# MOTOR register map
Registers are 32-bit, access not given, no defined reset value unless marked. A register's access mark holds for its fields unless they carry their own. Addresses are absolute; registers are grouped by the start of their names; [hi:lo] are bit positions; {n}, {i} and the like mark numbered series.

## OPTIONREG0
{0x40069200+4i} OPTIONREG0_{i}_0 (i=0..7)
  [15:0] TIMEBASE_OR0_{i}
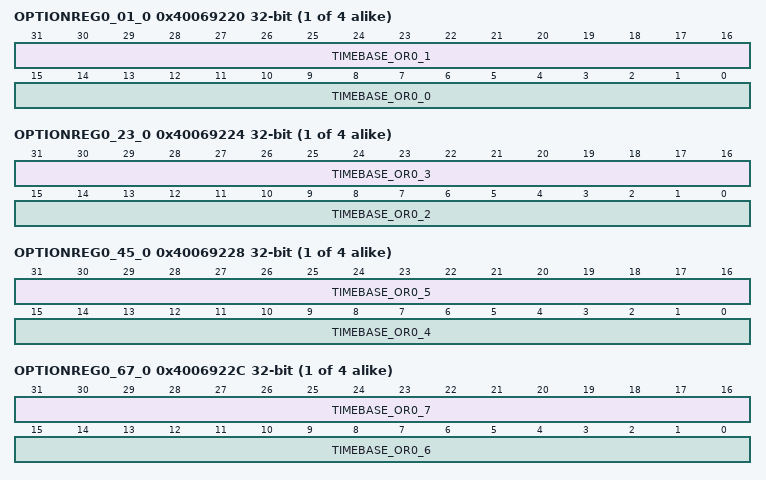
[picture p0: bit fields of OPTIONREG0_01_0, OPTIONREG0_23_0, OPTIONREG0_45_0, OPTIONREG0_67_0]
{0x40069220+0x400*i} OPTIONREG0_01_{i} (i=0..3)
  [31:16] TIMEBASE_OR0_1, [15:0] TIMEBASE_OR0_0
{0x40069224+0x400*i} OPTIONREG0_23_{i} (i=0..3)
  [31:16] TIMEBASE_OR0_3, [15:0] TIMEBASE_OR0_2
{0x40069228+0x400*i} OPTIONREG0_45_{i} (i=0..3)
  [31:16] TIMEBASE_OR0_5, [15:0] TIMEBASE_OR0_4
{0x4006922C+0x400*i} OPTIONREG0_67_{i} (i=0..3)
  [31:16] TIMEBASE_OR0_7, [15:0] TIMEBASE_OR0_6
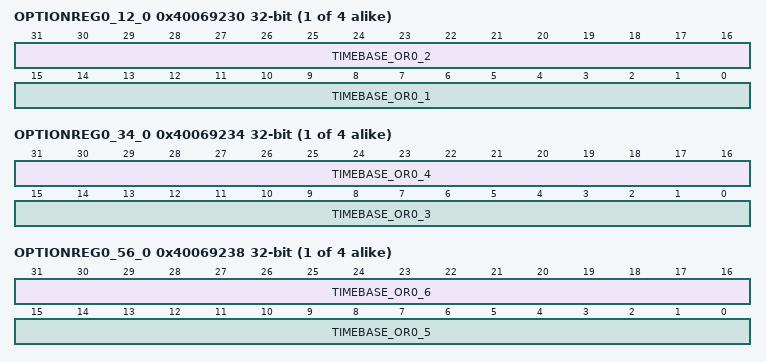
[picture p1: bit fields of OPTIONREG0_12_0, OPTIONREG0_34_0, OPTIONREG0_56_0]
{0x40069230+0x400*i} OPTIONREG0_12_{i} (i=0..3)
  [31:16] TIMEBASE_OR0_2, [15:0] TIMEBASE_OR0_1
{0x40069234+0x400*i} OPTIONREG0_34_{i} (i=0..3)
  [31:16] TIMEBASE_OR0_4, [15:0] TIMEBASE_OR0_3
{0x40069238+0x400*i} OPTIONREG0_56_{i} (i=0..3)
  [31:16] TIMEBASE_OR0_6, [15:0] TIMEBASE_OR0_5
{0x40069600+4i} OPTIONREG0_{i}_1 (i=0..7)
  [15:0] TIMEBASE_OR0_{i}
{0x40069A00+4i} OPTIONREG0_{i}_2 (i=0..7)
  [15:0] TIMEBASE_OR0_{i}
{0x40069E00+4i} OPTIONREG0_{i}_3 (i=0..7)
  [15:0] TIMEBASE_OR0_{i}

## OPTIONREG1
{0x40069240+4i} OPTIONREG1_{i}_0 (i=0..7)
  [15:0] TIMEBASE_OR1_{i}
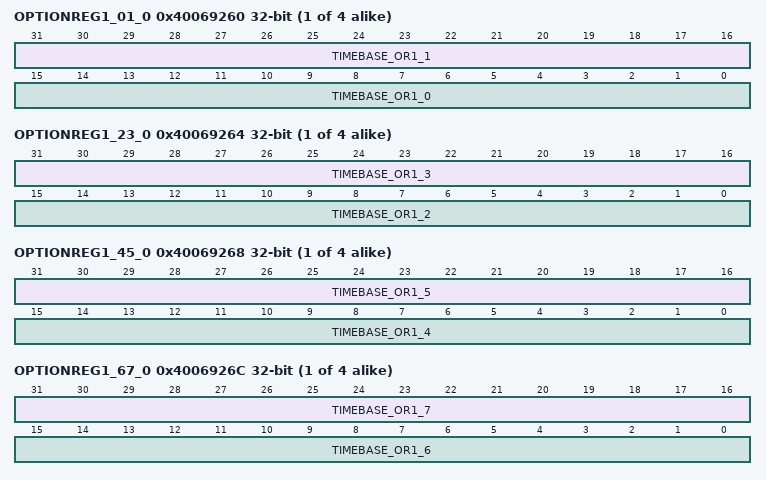
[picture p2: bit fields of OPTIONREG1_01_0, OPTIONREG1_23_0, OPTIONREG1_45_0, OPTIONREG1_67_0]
{0x40069260+0x400*i} OPTIONREG1_01_{i} (i=0..3)
  [31:16] TIMEBASE_OR1_1, [15:0] TIMEBASE_OR1_0
{0x40069264+0x400*i} OPTIONREG1_23_{i} (i=0..3)
  [31:16] TIMEBASE_OR1_3, [15:0] TIMEBASE_OR1_2
{0x40069268+0x400*i} OPTIONREG1_45_{i} (i=0..3)
  [31:16] TIMEBASE_OR1_5, [15:0] TIMEBASE_OR1_4
{0x4006926C+0x400*i} OPTIONREG1_67_{i} (i=0..3)
  [31:16] TIMEBASE_OR1_7, [15:0] TIMEBASE_OR1_6
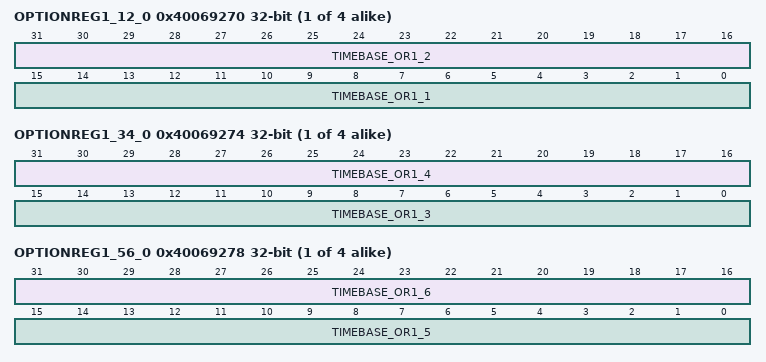
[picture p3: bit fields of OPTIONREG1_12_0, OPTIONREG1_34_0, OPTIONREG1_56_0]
{0x40069270+0x400*i} OPTIONREG1_12_{i} (i=0..3)
  [31:16] TIMEBASE_OR1_2, [15:0] TIMEBASE_OR1_1
{0x40069274+0x400*i} OPTIONREG1_34_{i} (i=0..3)
  [31:16] TIMEBASE_OR1_4, [15:0] TIMEBASE_OR1_3
{0x40069278+0x400*i} OPTIONREG1_56_{i} (i=0..3)
  [31:16] TIMEBASE_OR1_6, [15:0] TIMEBASE_OR1_5
{0x40069640+4i} OPTIONREG1_{i}_1 (i=0..7)
  [15:0] TIMEBASE_OR1_{i}
{0x40069A40+4i} OPTIONREG1_{i}_2 (i=0..7)
  [15:0] TIMEBASE_OR1_{i}
{0x40069E40+4i} OPTIONREG1_{i}_3 (i=0..7)
  [15:0] TIMEBASE_OR1_{i}

## OPTIONREG2
{0x40069280+4i} OPTIONREG2_{i}_0 (i=0..7)
  [15:0] TIMEBASE_OR2_{i}
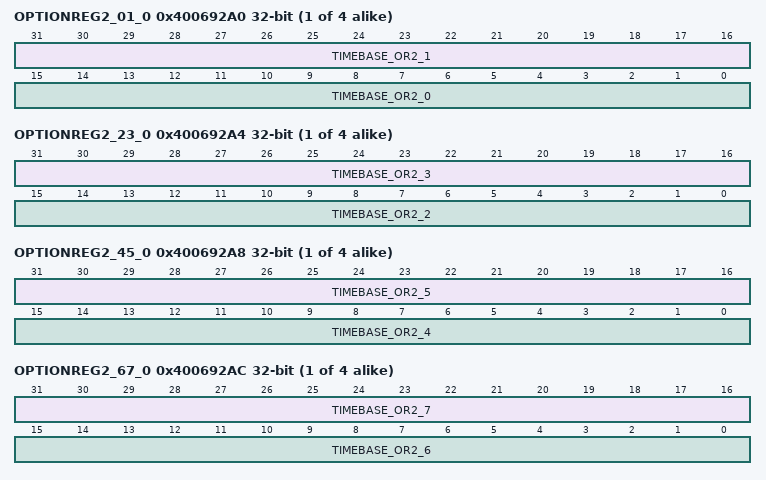
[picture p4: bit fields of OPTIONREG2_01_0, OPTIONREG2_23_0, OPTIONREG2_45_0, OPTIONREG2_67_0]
{0x400692A0+0x400*i} OPTIONREG2_01_{i} (i=0..3)
  [31:16] TIMEBASE_OR2_1, [15:0] TIMEBASE_OR2_0
{0x400692A4+0x400*i} OPTIONREG2_23_{i} (i=0..3)
  [31:16] TIMEBASE_OR2_3, [15:0] TIMEBASE_OR2_2
{0x400692A8+0x400*i} OPTIONREG2_45_{i} (i=0..3)
  [31:16] TIMEBASE_OR2_5, [15:0] TIMEBASE_OR2_4
{0x400692AC+0x400*i} OPTIONREG2_67_{i} (i=0..3)
  [31:16] TIMEBASE_OR2_7, [15:0] TIMEBASE_OR2_6
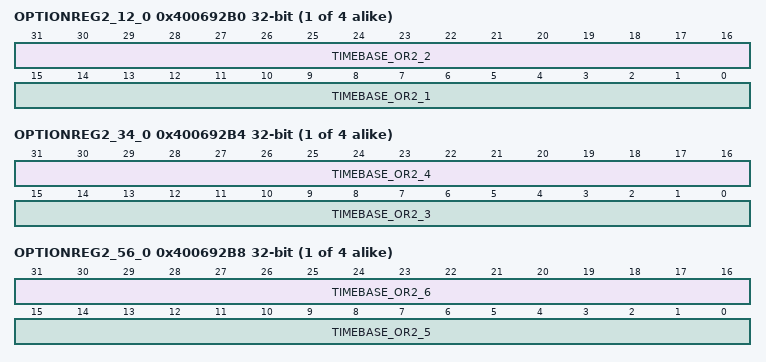
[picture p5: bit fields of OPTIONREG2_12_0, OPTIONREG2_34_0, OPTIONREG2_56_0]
{0x400692B0+0x400*i} OPTIONREG2_12_{i} (i=0..3)
  [31:16] TIMEBASE_OR2_2, [15:0] TIMEBASE_OR2_1
{0x400692B4+0x400*i} OPTIONREG2_34_{i} (i=0..3)
  [31:16] TIMEBASE_OR2_4, [15:0] TIMEBASE_OR2_3
{0x400692B8+0x400*i} OPTIONREG2_56_{i} (i=0..3)
  [31:16] TIMEBASE_OR2_6, [15:0] TIMEBASE_OR2_5
{0x40069680+4i} OPTIONREG2_{i}_1 (i=0..7)
  [15:0] TIMEBASE_OR2_{i}
{0x40069A80+4i} OPTIONREG2_{i}_2 (i=0..7)
  [15:0] TIMEBASE_OR2_{i}
{0x40069E80+4i} OPTIONREG2_{i}_3 (i=0..7)
  [15:0] TIMEBASE_OR2_{i}

## OPTIONREG3
{0x400692C0+4i} OPTIONREG3_{i}_0 (i=0..7)
  [15:0] TIMEBASE_OR3_{i}
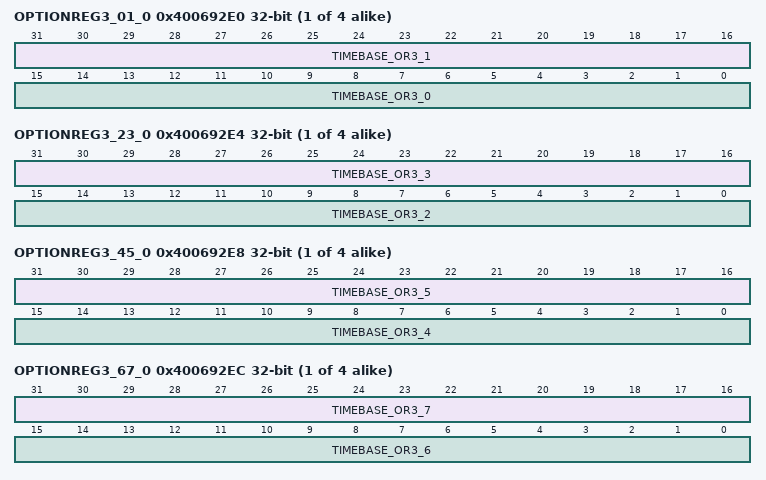
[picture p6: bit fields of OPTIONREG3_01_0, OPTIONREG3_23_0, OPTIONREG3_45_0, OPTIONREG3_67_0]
{0x400692E0+0x400*i} OPTIONREG3_01_{i} (i=0..3)
  [31:16] TIMEBASE_OR3_1, [15:0] TIMEBASE_OR3_0
{0x400692E4+0x400*i} OPTIONREG3_23_{i} (i=0..3)
  [31:16] TIMEBASE_OR3_3, [15:0] TIMEBASE_OR3_2
{0x400692E8+0x400*i} OPTIONREG3_45_{i} (i=0..3)
  [31:16] TIMEBASE_OR3_5, [15:0] TIMEBASE_OR3_4
{0x400692EC+0x400*i} OPTIONREG3_67_{i} (i=0..3)
  [31:16] TIMEBASE_OR3_7, [15:0] TIMEBASE_OR3_6
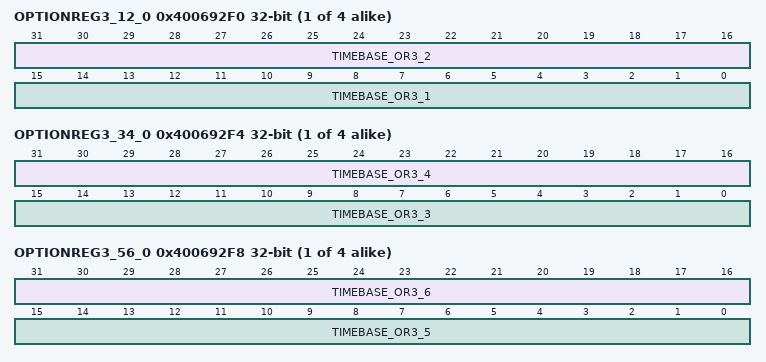
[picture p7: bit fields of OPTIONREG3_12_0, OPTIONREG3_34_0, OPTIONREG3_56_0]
{0x400692F0+0x400*i} OPTIONREG3_12_{i} (i=0..3)
  [31:16] TIMEBASE_OR3_2, [15:0] TIMEBASE_OR3_1
{0x400692F4+0x400*i} OPTIONREG3_34_{i} (i=0..3)
  [31:16] TIMEBASE_OR3_4, [15:0] TIMEBASE_OR3_3
{0x400692F8+0x400*i} OPTIONREG3_56_{i} (i=0..3)
  [31:16] TIMEBASE_OR3_6, [15:0] TIMEBASE_OR3_5
{0x400696C0+4i} OPTIONREG3_{i}_1 (i=0..7)
  [15:0] TIMEBASE_OR3_{i}
{0x40069AC0+4i} OPTIONREG3_{i}_2 (i=0..7)
  [15:0] TIMEBASE_OR3_{i}
{0x40069EC0+4i} OPTIONREG3_{i}_3 (i=0..7)
  [15:0] TIMEBASE_OR3_{i}
